# S32R372 register map
Vendor: Freescale Semiconductor, Inc.; Series: Qorivva; File version: 1.6
Registers are 32-bit, read-write, reset 0x0 unless marked. A register's access mark holds for its fields unless they carry their own. Offsets are from the block's base; [hi:lo] are bit positions; {n}, {i} and the like mark numbered series; 'fields as' and 'values as' point back to an identical list.

## C55FMC
Base 0xFFFE0000; register names take the prefix C55FMC_
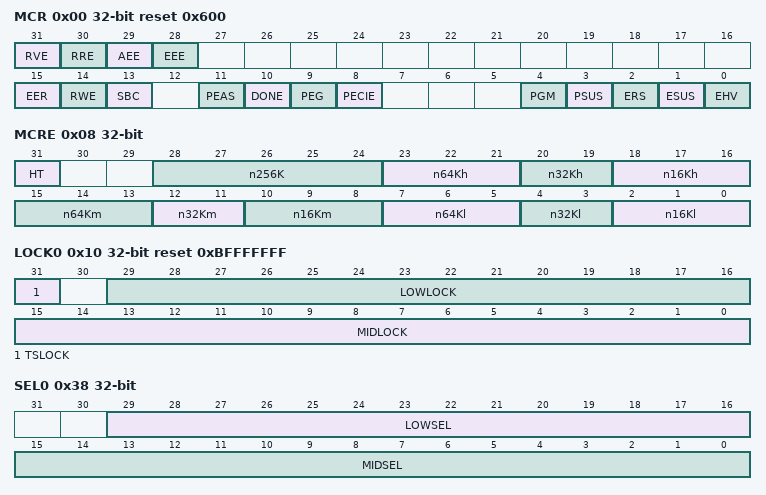
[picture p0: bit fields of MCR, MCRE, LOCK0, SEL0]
0x00 MCR reset 0x600 — Module Configuration Register
  [31] RVE — Read Voltage Error
    0=Reads are occurring without voltage issues; 1=A previous read may have been corrupted due to read voltage being out of range
  [30] RRE — Read Reference Error
    0=Reads are occurring without reference issues; 1=A previous read may have been corrupted due to read reference being out of range
  [29] AEE — Address Encode Error
    0=Reads are occurring without address encode mismatches; 1=A previous read may be corrupted based on address encode mismatch
  [28] EEE — ECC after ECC Error
    0=Reads are occurring without ECC after ECC mismatches; 1=A previous read may be corrupted based on ECC calculation errors
  [15] EER — ECC Event Error
    0=Reads are occurring normally; 1=An ECC Error occurred during a previous read
  [14] RWE — Read-While-Write Event Error
    0=Reads are occurring normally; 1=A read-while-write error occurred during a previous read
  [13] SBC — Single Bit Correction
    0=Reads are occurring without corrections; 1=A Single Bit Correction occurred during a previous read
  [11] PEAS ro — Program Access Space
    0=UTest NVM address space is disabled for program/erase and main address space enabled; 1=UTest NVM address space is enabled for program/erase and main address space disabled
  [10] DONE ro — State Machine Status
    0=Flash memory is executing a high voltage operation; 1=Flash memory is not executing a high voltage operation
  [9] PEG ro — Program/Erase Good
    0=Program or erase operation failed; 1=Program or erase operation successful
  [8] PECIE — Program/Erase Complete Interrupt Enable
    0=An interrupt request will not be generated when the DONE flag is set; 1=An interrupt request will be generated when the DONE flag is set
  [4] PGM — Program
    0=Flash memory is not executing a program sequence; 1=Flash memory is executing a program sequence
  [3] PSUS — Program Suspend
    0=Program sequence is not suspended; 1=Program sequence is suspended
  [2] ERS — Erase
    0=Flash memory is not executing an erase sequence; 1=Flash memory is executing an erase sequence
  [1] ESUS — Erase Suspend
    0=Erase sequence is not suspended; 1=Erase sequence is suspended
  [0] EHV — Enable High Voltage
    0=Flash memory is not enabled to perform a high voltage operation; 1=Flash memory is enabled to perform a high voltage operation
0x08 MCRE ro — Extended Module Configuration Register
  [31] HT — High Temperature Enabled.
    0=150 degree C maximum operating temperature. 165 degree C operating temperature maximum is not supported on this device.
  [28:24] n256K — Number of 256 KB blocks
    0=Zero 256 KB blocks; 1=Two 256 KB blocks (512 KB total); 2=Four 256 KB blocks (1 MB total); 3=Six 256 KB blocks (1.5 MB total); 4=Eight 256 KB blocks (2 MB total); 5=Ten 256 KB blocks (2.5 MB total); 6=Twelve 256 KB blocks (3 MB total); 7=Fourteen 256 KB blocks (3.5 MB total); 8=Sixteen 256 KB blocks (4 MB total); 9=Eighteen 256 KB blocks (4.5 MB total); 10=Twenty 256 KB blocks (5 MB total); 11=Twenty-two 256 KB blocks (5.5 MB total); 12=Twenty-four 256 KB blocks (6 MB total); 13=Twenty-six 256 KB blocks (6.5 MB total); 14=Twenty-eight 256 KB blocks (7 MB total); 15=Thirty 256 KB blocks (7.5 MB total); 16=Thirty-two 256 KB blocks (8 MB total); 24=Forty-eight 256 KB blocks (12 MB total)
  [23:21] n64Kh — Number of 64 KB blocks in partitions 4 and 5. This field is read only.
    0=Zero 64 KB blocks; 1=Two 64 KB blocks; 2=Four 64 KB blocks; 3=Six 64 KB blocks; 4=Eight 64 KB blocks; 5=Twelve 64 KB blocks; 6=Sixteen 64 KB blocks
  [20:19] n32Kh — Number of 32 KB blocks in partitions 4 and 5. This field is read only.
    0=Zero 32 KB blocks; 1=Two 32 KB blocks; 2=Four 32 KB blocks
  [18:16] n16Kh — Number of 16 KB blocks in partitions 4 and 5. This field is read only.
    0=Zero 16 KB blocks; 1=Two 16 KB blocks; 2=Four 16 KB blocks; 3=Six 16 KB blocks; 4=Eight 16 KB blocks
  [15:13] n64Km — Number of 64 KB blocks in partitions 2 and 3. This field is read only.
    0=Zero 64 KB blocks; 1=Two 64 KB blocks; 2=Four 64 KB blocks; 3=Six 64 KB blocks; 4=Eight 64 KB blocks
  [12:11] n32Km — Number of 32 KB blocks in partitions 2 and 3. This field is read only.
    0=Zero 32 KB blocks; 1=Two 32 KB blocks; 2=Four 32 KB blocks
  [10:8] n16Km — Number of 16 KB blocks in partitions 2 and 3. This field is read only.
    values as n16Kh
  [7:5] n64Kl — Number of 64 KB blocks in partitions 0 and 1. This field is read only.
    values as n64Km
  [4:3] n32Kl — Number of 32 KB blocks in partitions 0 and 1. This field is read only.
    0=Zero 32 KB blocks; 1=Two 32 KB blocks; 2=Four 32 KB blocks
  [2:0] n16Kl — Number of 16 KB blocks in partitions 0 and 1. This field is read only.
    0=Zero 16 KB blocks; 1=Two 16 KB blocks; 2=Four 16 KB blocks; 3=Six 16 KB blocks
0x10 LOCK0 reset 0xBFFFFFFF
  [31] TSLOCK — UTest NVM Lock.
    0=UTest NVM block is available to be programmed; 1=UTest NVM block is locked and cannot be programmed
  [29:16] LOWLOCK — Low Block Lock
    0=Block is available for program and erase operations; 1=Block is locked and unavailable for program and erase operations
  [15:0] MIDLOCK — Mid Block Lock
    values as LOWLOCK
0x14 LOCK1 reset 0xFFFF
  [15:0] HIGHLOCK — High Block Lock
    values as LOCK0.LOWLOCK
0x18 LOCK2 reset 0xFFFFFFFF
  [31:0] A256KLOCK — 256 KB Block Lock
    values as LOCK0.LOWLOCK
0x1C LOCK3 reset 0xFFFF
  [15:0] A256KLOCK — 256 KB Block Lock
    values as LOCK0.LOWLOCK
0x38 SEL0 — Select 0 register
  [29:16] LOWSEL — LOW Block Select.
    0=The block is not selected; 1=The block is selected for erase
  [15:0] MIDSEL — Mid Block Select.
    values as LOWSEL
0x3C SEL1 — Select 1 register
  [15:0] HIGHSEL — High Block Select.
    0=The block is not selected for erase; 1=The block is selected for erase
0x40 SEL2 — Select 2 register
  [31:0] A256KSEL — 256 KB Block Select.
    values as SEL0.LOWSEL
0x44 SEL3 — Select 3 register
  [15:0] A256KSEL — 256 KB Block Select.
    1=The block is selected for erase; 0=The block is not selected
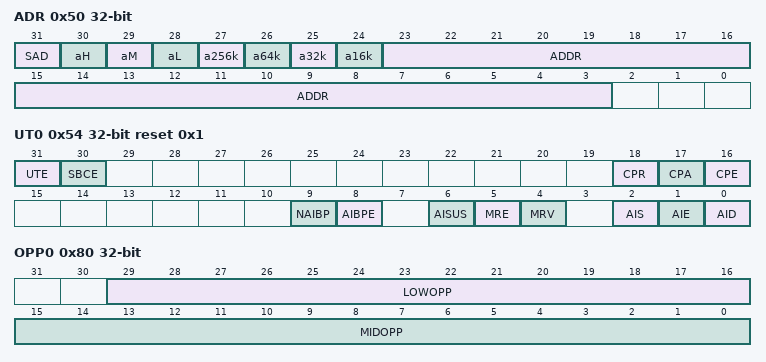
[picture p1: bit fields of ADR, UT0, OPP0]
0x50 ADR ro — Address register
  [31] SAD — UTest NVM Address
    0=Address captured is from main array Space; 1=Address captured is from UTest NVM array space
  [30] aH — Address High region
    0=Address captured or to be accessed is not from high address region; 1=Address captured or to be accessed is from high address region
  [29] aM — Address Mid region
    0=Address captured or to be accessed is not from mid address region; 1=Address captured or to be accessed is from mid address region
  [28] aL — Address Low region
    0=Address captured or to be accessed is not from low address region; 1=Address captured or to be accessed is from low address region
  [27] a256k — Address 256 KB region
    0=Address captured or to be accessed is not from 256 KB region; 1=Address captured or to be accessed is from 256 KB region
  [26] a64k — Address 64 KB region
    0=Address captured or to be accessed is not from 64 KB region; 1=Address captured or to be accessed is from 64 KB region
  [25] a32k — Address 32 KB region
    0=Address captured or to be accessed is not from 32 KB region; 1=Address captured or to be accessed is from 32 KB region
  [24] a16k — Address 16 KB region
    0=Address captured or to be accessed is not from 16 KB region; 1=Address captured or to be accessed is from 16 KB region
  [23:3] ADDR — Address
0x54 UT0 reset 0x1 — UTest 0 register
  [31] UTE — U-Test Enable
    0=All bits in the UT0, UM0, UM1, UM2, UM3, UM4, UM5, UM6, UM7, UM8 and UM9 registers are locked; 1=Bits in the UT0, UM0, UM1, UM2, UM3, UM4, UM5, UM6, UM7, UM8 and UM9 registers are unlocked
  [30] SBCE — Single Bit Correction Enable
    0=Single Bit Corrections observation is disabled; 1=Single Bit Correction observation is enabled
  [18] CPR — Customer Programmable Read Voltage and Reference Detection
    0=Customer Programmable Read Voltage and Reference Detection Error is not enabled; 1=Customer Programmable Read Voltage and Reference Detection Error is enabled
  [17] CPA — Customer Programmable Address Encode Detection
    0=Customer Programmable Address Encode Detection Error is not enabled; 1=Customer Programmable Address Encode Detection Error is enabled
  [16] CPE — Customer Programmable EDC after ECC Detection
    0=Customer Programmable EDC after ECC Detection Error is not enabled; 1=Customer Programmable EDC after ECC Detection Error is enabled
  [9] NAIBP — Next Array Integrity Break Point
    1=Array Integrity state machine is at a break point; 0=Array Integrity state machine is not currently at a break point
  [8] AIBPE — Array Integrity Break Point Enable
    1=Array Integrity breakpoints are enabled during Array Integrity Checks; 0=Array Integrity breakpoints are not enabled
  [6] AISUS — Array Integrity Suspend
    1=Array integrity sequence is suspended; 0=Array integrity sequence not suspended
  [5] MRE — Margin Read Enable
    1=Margin reads are enabled; 0=Margin reads are not enabled
  [4] MRV — Margin Read Value
    1=One's margin reads are requested; 0=Zero's margin reads are requested
  [2] AIS — Array Integrity Sequence
    1=Array integrity sequence is sequential; 0=Array integrity sequence is proprietary sequence
  [1] AIE — Array Integrity Enable
    0=Array integrity checks are not enabled; 1=Array integrity checks are enabled
  [0] AID ro — Array Integrity Done
    0=Array integrity check is ongoing; 1=Array integrity check is done
{0x58+4i} UM{i} (i=0..8) — UMISR register
  [31:0] MISR — MISR[31:0]
0x7C UM9 — UMISR register
  [0] MISR — MISR[288].
0x80 OPP0 ro — Over-Program Protection 0 register
  [29:16] LOWOPP — Low Block Over-Program Protection[13:0].
    1=The corresponding block is protected from over-programming; 0=The corresponding block is available to be over-programmed
  [15:0] MIDOPP — Mid Block Over-Program Protection[15:0].
    values as LOWOPP
0x84 OPP1 ro — Over-Program Protection 1 register
  [15:0] HIGHOPP — High Block Over-Program Protection[15:0].
    values as OPP0.LOWOPP
0x88 OPP2 ro — Over-Program Protection 2 register
  [31:0] A256KOPP — 256K Block Over-Program Protection[31:0].
    1=The corresponding block is protected from over-programming; 0=0 The corresponding block is available to be over-programmed
0x8C OPP3 ro — Over-Program Protection 3 register
  [15:0] A256KOPP — 256K Block Over-Program Protection[47:32].
    values as OPP0.LOWOPP
0x90 TMD — Test Mode Disable Password Check register
  [31:0] PWD — Password challenge
